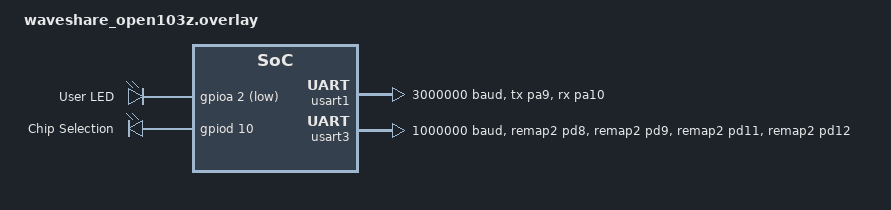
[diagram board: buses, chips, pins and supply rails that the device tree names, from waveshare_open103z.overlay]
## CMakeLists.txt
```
# SPDX-License-Identifier: Apache-2.0

cmake_minimum_required(VERSION 3.20.0)
find_package(Zephyr REQUIRED HINTS $ENV{ZEPHYR_BASE})
project(demo)

target_sources(app PRIVATE
  src/main.c
  src/vnd_srv.c
)
```

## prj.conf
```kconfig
# Increased stack due to settings API usage
CONFIG_SYSTEM_WORKQUEUE_STACK_SIZE=2048

CONFIG_BT=y
CONFIG_BT_H4=y
CONFIG_BT_DEBUG_LOG=y
CONFIG_BT_SMP=y
CONFIG_BT_GATT_CLIENT=y
CONFIG_BT_SIGNING=y
CONFIG_BT_PERIPHERAL=y
CONFIG_BT_DIS=y
CONFIG_BT_ATT_PREPARE_COUNT=5
CONFIG_BT_BAS=y
CONFIG_BT_HRS=y
CONFIG_BT_TPS=y
CONFIG_BT_PRIVACY=y
CONFIG_BT_DEVICE_APPEARANCE=833
CONFIG_BT_BUF_ACL_RX_SIZE=251
CONFIG_BT_L2CAP_TX_MTU=247
CONFIG_BT_TINYCRYPT_ECC=y
CONFIG_BT_REMOTE_INFO=y
CONFIG_BT_REMOTE_VERSION=y
CONFIG_BT_KEYS_OVERWRITE_OLDEST=y
CONFIG_BT_USER_DATA_LEN_UPDATE=y

CONFIG_SHELL=y
CONFIG_KERNEL_SHELL=y
CONFIG_DEVICE_SHELL=y

CONFIG_REBOOT=y
```

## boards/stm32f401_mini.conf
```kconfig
CONFIG_BT_DEVICE_NAME="Zephyr on STM32F4"
```

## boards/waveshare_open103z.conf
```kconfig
CONFIG_BT_DEVICE_NAME="Zephyr on Doflye"
CONFIG_BT_SETTINGS=y

CONFIG_FLASH=y
CONFIG_FLASH_PAGE_LAYOUT=y
CONFIG_FLASH_MAP=y
CONFIG_NVS=y
CONFIG_SETTINGS=y
CONFIG_SETTINGS_NVS=y
```

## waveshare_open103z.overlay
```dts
/ {
    leds {
        compatible = "gpio-leds";
        user_led: user_led {
            gpios = <&gpioa 2 GPIO_ACTIVE_LOW>;
            label = "User LED";
        };
        bt_cs: bt_cs {
            gpios = <&gpiod 10 GPIO_ACTIVE_HIGH>;
            label = "Chip Selection";
        };
    };

    aliases {
        led = &user_led;
        cs = &bt_cs;
    };

    chosen {
        zephyr,bt-uart = &usart3;
    };
};

&flash0 {
    partitions {
        compatible = "fixed-partitions";
        #address-cells = <1>;
        #size-cells = <1>;

        /* Set 16Kb of storage at the end of the 512Kb of flash */
        storage_partition: partition@7c000 {
            label = "storage";
            reg = <0x0007c000 DT_SIZE_K(16)>;
        };
    };
};

&usart1 {
    pinctrl-0 = <&usart1_tx_pa9 &usart1_rx_pa10>;
    pinctrl-names = "default";
    current-speed = <3000000>;
    status = "okay";
};

&usart3 {
    pinctrl-0 = <&usart3_tx_remap2_pd8 &usart3_rx_remap2_pd9 &usart3_cts_remap2_pd11 &usart3_rts_remap2_pd12>;
    pinctrl-names = "default";
    current-speed = <1000000>;
    hw-flow-control;
    status = "okay";
};
```

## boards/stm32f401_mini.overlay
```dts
/ {
    chosen {
        zephyr,bt-uart = &usart1;
        zephyr,console = &usart2;
        zephyr,shell-uart = &usart2;
    };
};

&usart1 {
    pinctrl-0 = <&usart1_tx_pa9 &usart1_rx_pa10 &usart1_cts_pa11 &usart1_rts_pa12>;
    pinctrl-names = "default";
    status = "okay";
    current-speed = <1000000>;
    hw-flow-control;
};

&usart2 {
    pinctrl-0 = <&usart2_tx_pa2 &usart2_rx_pa3>;
    pinctrl-names = "default";
    status = "okay";
    current-speed = <921600>;
};
```

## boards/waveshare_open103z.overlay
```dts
/ {
    leds {
        compatible = "gpio-leds";
        user_led: user_led {
            gpios = <&gpioa 2 GPIO_ACTIVE_LOW>;
            label = "User LED";
        };
        bt_cs: bt_cs {
            gpios = <&gpiod 10 GPIO_ACTIVE_HIGH>;
            label = "Chip Selection";
        };
    };

    aliases {
        led = &user_led;
        cs = &bt_cs;
    };

    chosen {
        zephyr,bt-uart = &usart3;
    };
};

&flash0 {
    partitions {
        compatible = "fixed-partitions";
        #address-cells = <1>;
        #size-cells = <1>;

        /* Set 16Kb of storage at the end of the 512Kb of flash */
        storage_partition: partition@7c000 {
            label = "storage";
            reg = <0x0007c000 DT_SIZE_K(16)>;
        };
    };
};

&usart1 {
    pinctrl-0 = <&usart1_tx_pa9 &usart1_rx_pa10>;
    pinctrl-names = "default";
    current-speed = <3000000>;
    status = "okay";
};

&usart3 {
    pinctrl-0 = <&usart3_tx_remap2_pd8 &usart3_rx_remap2_pd9 &usart3_cts_remap2_pd11 &usart3_rts_remap2_pd12>;
    pinctrl-names = "default";
    current-speed = <1000000>;
    hw-flow-control;
    status = "okay";
};
```

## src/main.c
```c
/* main.c - Application main entry point */

/*
 * Copyright (c) 2015-2016 Intel Corporation
 *
 * SPDX-License-Identifier: Apache-2.0
 */

#include <zephyr/types.h>
#include <stddef.h>
#include <string.h>
#include <errno.h>
#include <zephyr/sys/byteorder.h>
#include <zephyr/sys/reboot.h>
#include <zephyr/kernel.h>
#include <zephyr/settings/settings.h>
#include <zephyr/drivers/gpio.h>

#include <zephyr/bluetooth/bluetooth.h>
#include <zephyr/bluetooth/hci.h>
#include <zephyr/bluetooth/conn.h>
#include <zephyr/bluetooth/uuid.h>
#include <zephyr/bluetooth/gatt.h>
#include <zephyr/bluetooth/services/bas.h>
#include <zephyr/bluetooth/services/hrs.h>

#include <zephyr/logging/log.h>
LOG_MODULE_REGISTER(demo);

int bt_long_vnd_notify(void);

/* The devicetree node identifier for the "led0" alias. */
#define LED_NODE DT_ALIAS(led0)

/*
 * A build error on this line means your board is unsupported.
 * See the sample documentation for information on how to fix this.
 */
static const struct gpio_dt_spec led = GPIO_DT_SPEC_GET(LED_NODE, gpios);

static const struct bt_data ad[] = {
    BT_DATA_BYTES(BT_DATA_FLAGS, (BT_LE_AD_GENERAL | BT_LE_AD_NO_BREDR)),
    BT_DATA_BYTES(BT_DATA_UUID16_ALL,
              BT_UUID_16_ENCODE(BT_UUID_HRS_VAL),
              BT_UUID_16_ENCODE(BT_UUID_BAS_VAL),
              BT_UUID_16_ENCODE(BT_UUID_CTS_VAL),
              BT_UUID_16_ENCODE(BT_UUID_TPS_VAL)),
};

static uint16_t appearance = sys_cpu_to_le16(CONFIG_BT_DEVICE_APPEARANCE);

/* Set Scan Response data */
static const struct bt_data sd[] = {
    BT_DATA(BT_DATA_GAP_APPEARANCE, &appearance, sizeof(appearance)),
};

static void mtu_exchange_cb(struct bt_conn *conn, uint8_t err,
                struct bt_gatt_exchange_params *params)
{
    LOG_INF("MTU exchange %u %s (%u)", bt_conn_index(conn),
           err == 0U ? "successful" : "failed", bt_gatt_get_mtu(conn));
}

static void connected(struct bt_conn *conn, uint8_t err)
{
    char addr[BT_ADDR_LE_STR_LEN];
    int ret;
    static struct bt_gatt_exchange_params params = {
        .func = mtu_exchange_cb,
    };

    if (err) {
        LOG_ERR("Connection failed (err 0x%02x)", err);
        return;
    }

    bt_addr_le_to_str(bt_conn_get_dst(conn), addr, sizeof(addr));
    LOG_INF("Connected to %s", addr);

    ret = bt_gatt_exchange_mtu(conn, &params);
    if (ret) {
        LOG_ERR("MTU exchange failed (err %d)", ret);
        return;
    }
}

static void disconnected(struct bt_conn *conn, uint8_t reason)
{
    LOG_INF("Disconnected (reason 0x%02x)", reason);
}

static void remote_info_available(struct bt_conn *conn, struct bt_conn_remote_info *remote_info)
{
    uint8_t features[8];
    char features_str[2 * sizeof(features) +  1] = {0};

    LOG_INF("Remote LMP version 0x%02x subversion 0x%04x manufacturer 0x%04x",
                remote_info->version, remote_info->subversion, remote_info->manufacturer);

    sys_memcpy_swap(features, remote_info->le.features, sizeof(features));
    bin2hex(features, sizeof(features), features_str, sizeof(features_str));

    LOG_INF("LE Features: 0x%s ", features_str);
}

static void le_data_len_updated(struct bt_conn *conn, struct bt_conn_le_data_len_info *info)
{
    char addr[BT_ADDR_LE_STR_LEN];

    bt_addr_le_to_str(bt_conn_get_dst(conn), addr, sizeof(addr));

    LOG_INF("Data length updated: %s max tx %u (%u us) max rx %u (%u us)\n",
           addr, info->tx_max_len, info->tx_max_time, info->rx_max_len,
           info->rx_max_time);
}

BT_CONN_CB_DEFINE(conn_callbacks) = {
    .connected = connected,
    .disconnected = disconnected,
    .remote_info_available = remote_info_available,
    .le_data_len_updated = le_data_len_updated,
};

static void auth_passkey_display(struct bt_conn *conn, unsigned int passkey)
{
    char addr[BT_ADDR_LE_STR_LEN];

    bt_addr_le_to_str(bt_conn_get_dst(conn), addr, sizeof(addr));

    LOG_INF("Passkey for %s: %06u", addr, passkey);
}

static void auth_cancel(struct bt_conn *conn)
{
    char addr[BT_ADDR_LE_STR_LEN];

    bt_addr_le_to_str(bt_conn_get_dst(conn), addr, sizeof(addr));

    LOG_INF("Pairing cancelled: %s", addr);
}

static struct bt_conn_auth_cb auth_cb_display = {
    .passkey_display = auth_passkey_display,
    .passkey_entry = NULL,
    .cancel = auth_cancel,
};

static void bas_notify(void)
{
    uint8_t battery_level = bt_bas_get_battery_level();

    battery_level--;

    if (!battery_level) {
        battery_level = 100U;
    }

    bt_bas_set_battery_level(battery_level);
}

static void hrs_notify(void)
{
    static uint8_t heartrate = 90U;

    /* Heartrate measurements simulation */
    heartrate++;
    if (heartrate == 160U) {
        heartrate = 90U;
    }

    bt_hrs_notify(heartrate);
}

void main(void)
{
    int err;

    if (!device_is_ready(led.port)) {
        LOG_ERR("LED is not ready");
        return;
    }

    err = gpio_pin_configure_dt(&led, GPIO_OUTPUT_ACTIVE);
    if (err < 0) {
        LOG_ERR("Configure LED pin failed (err %d)", err);
        return;
    }

    err = bt_enable(NULL);
    if (err) {
        LOG_ERR("Bluetooth init failed (err %d)", err);
        return;
    }

    LOG_INF("Bluetooth initialized");

    if (IS_ENABLED(CONFIG_SETTINGS)) {
        settings_load();
    }

    bt_conn_auth_cb_register(&auth_cb_display);

    err = bt_le_adv_start(BT_LE_ADV_CONN_NAME, ad, ARRAY_SIZE(ad), sd, ARRAY_SIZE(sd));
    if (err) {
        LOG_ERR("Advertising failed to start (err %d)", err);
        return;
    }

    LOG_INF("Advertising successfully started");

    /* Implement notification. At the moment there is no suitable way
     * of starting delayed work so we do it here
     */
    while (1) {
        k_sleep(K_SECONDS(1));

        /* Heartrate measurements simulation */
        hrs_notify();

        /* Battery level simulation */
        bas_notify();

        /* Vendor service simulation */
        bt_long_vnd_notify();

        /* Toggle LED pin */
        gpio_pin_toggle_dt(&led);
    }
}
```

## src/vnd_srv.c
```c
#include <zephyr/types.h>
#include <stddef.h>
#include <string.h>
#include <errno.h>
#include <zephyr/sys/byteorder.h>
#include <zephyr/sys/reboot.h>
#include <zephyr/kernel.h>
#include <zephyr/settings/settings.h>

#include <zephyr/bluetooth/bluetooth.h>
#include <zephyr/bluetooth/hci.h>
#include <zephyr/bluetooth/conn.h>
#include <zephyr/bluetooth/uuid.h>
#include <zephyr/bluetooth/gatt.h>

#include <zephyr/logging/log.h>
LOG_MODULE_REGISTER(vendor);

/* Custom Service Variables */
#define BT_UUID_CUSTOM_SERVICE_VAL         BT_UUID_128_ENCODE(0x12345678, 0x1234, 0x5678, 0x1234, 0x56789abcdef0)
#define BT_UUID_CUSTOM_CHARACTERISTICS_VAL BT_UUID_128_ENCODE(0x12345678, 0x1234, 0x5678, 0x1234, 0x56789abcdef1)

static struct bt_uuid_128 vnd_uuid = BT_UUID_INIT_128(BT_UUID_CUSTOM_SERVICE_VAL);
static const struct bt_uuid_128 vnd_long_uuid = BT_UUID_INIT_128(BT_UUID_CUSTOM_CHARACTERISTICS_VAL);
static uint8_t vnd_long_value[CONFIG_BT_L2CAP_TX_MTU - 3] = {0};

static ssize_t read_long_vnd(struct bt_conn *conn, const struct bt_gatt_attr *attr,
                        void *buf, uint16_t len, uint16_t offset)
{
    const char *value = attr->user_data;

    return bt_gatt_attr_read(conn, attr, buf, len, offset, value, sizeof(vnd_long_value));
}

static ssize_t write_long_vnd(struct bt_conn *conn, const struct bt_gatt_attr *attr,
                        const void *buf, uint16_t len, uint16_t offset, uint8_t flags)
{
    uint8_t *value = attr->user_data;

    if (offset + len > sizeof(vnd_long_value)) {
        return BT_GATT_ERR(BT_ATT_ERR_INVALID_OFFSET);
    }

    memcpy(value + offset, buf, len);
    return len;
}

static void long_vnd_ccc_cfg_changed(const struct bt_gatt_attr *attr, uint16_t value)
{
    ARG_UNUSED(attr);

    bool notif_enabled = (value == BT_GATT_CCC_NOTIFY);

    LOG_INF("Vendor service Notifications %s", notif_enabled ? "enabled" : "disabled");
}

/* Vendor Primary Service Declaration */
BT_GATT_SERVICE_DEFINE(vnd_svc,
    BT_GATT_PRIMARY_SERVICE(&vnd_uuid),
    BT_GATT_CHARACTERISTIC(&vnd_long_uuid.uuid,
                BT_GATT_CHRC_READ | BT_GATT_CHRC_WRITE | BT_GATT_CHRC_NOTIFY,
                BT_GATT_PERM_READ_ENCRYPT | BT_GATT_PERM_WRITE_ENCRYPT,
                read_long_vnd, write_long_vnd, vnd_long_value),
    BT_GATT_CCC(long_vnd_ccc_cfg_changed, BT_GATT_PERM_READ | BT_GATT_PERM_WRITE),
);

int bt_long_vnd_notify(void)
{
    int ret;

    ret = bt_rand(vnd_long_value, sizeof(vnd_long_value));
    if (ret) {
        LOG_ERR("Generate random data failed (err %d)", ret);
        return ret;
    }

    ret = bt_gatt_notify(NULL, &vnd_svc.attrs[1], vnd_long_value, sizeof(vnd_long_value));

    return (ret == -ENOTCONN) ? 0 : ret;
}
```
